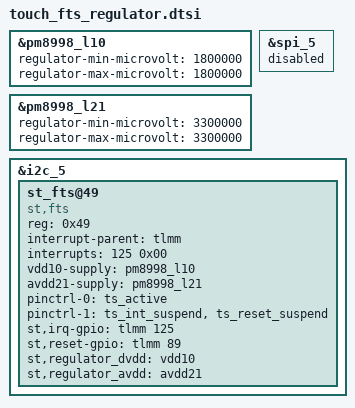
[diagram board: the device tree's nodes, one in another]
&pm8998_l10{
	regulator-min-microvolt = <1800000>;
	regulator-max-microvolt = <1800000>;
	status = "okay";
};

&pm8998_l21{
	regulator-min-microvolt = <3300000>;
	regulator-max-microvolt = <3300000>;
	status = "okay";
};

&spi_5{
	status = "disabled";
};

&i2c_5{
	status = "ok";
	st_fts@49 {
		compatible = "st,fts";
		reg = <0x49>;						//SAD
		interrupt-parent = <&tlmm>;
		interrupts = <125 0x00>;
		vdd10-supply = <&pm8998_l10>;			//1.8V power regulator
		avdd21-supply = <&pm8998_l21>;			//3.3V power regulator
		pinctrl-names = "pmx_ts_active", "pmx_ts_suspend";
		pinctrl-0 = <&ts_active>;
		pinctrl-1 = <&ts_int_suspend &ts_reset_suspend>;
		st,irq-gpio = <&tlmm 125 0x00>;		//interrupt gpio
		st,reset-gpio = <&tlmm 89 0x00>;		//specify the gpio which control the reset pin of the IC (if available, not mandatory)
		st,regulator_dvdd = "vdd10";
		st,regulator_avdd = "avdd21";
	};
};
